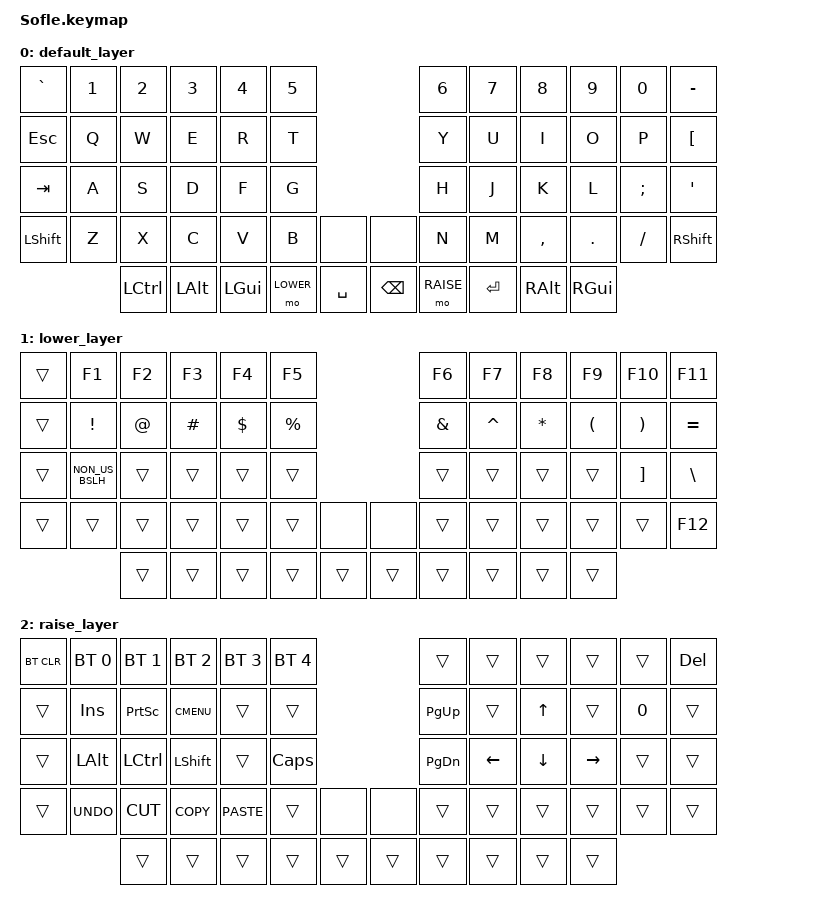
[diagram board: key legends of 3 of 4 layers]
/*
 * Copyright (c) 2020 The ZMK Contributors
 *
 * SPDX-License-Identifier: MIT
 */

#include <behaviors.dtsi>
#include <dt-bindings/zmk/keys.h>
#include <dt-bindings/zmk/bt.h>

#define BASE 0
#define LOWER 1
#define RAISE 2
#define ADJUST 3

/ {
    // Activate ADJUST layer by pressing raise and lower
    conditional_layers {
        compatible = "zmk,conditional-layers";
        adjust_layer {
            if-layers = <LOWER RAISE>;
            then-layer = <ADJUST>;
        };
    };

    keymap {
        compatible = "zmk,keymap";

        default_layer {
// ------------------------------------------------------------------------------------------------------------
// |  ½    |  1  |  2  |  3   |  4   |  5   |                   |  6   |  7    |  8    |  9   |   0   |   +   |
// |  ESC  |  Q  |  W  |  E   |  R   |  T   |                   |  Y   |  U    |  I    |  O   |   P   |   Å   |
// |  TAB  |  A  |  S  |  D   |  F   |  G   |                   |  H   |  J    |  K    |  L   |   Æ   |   Ø   |
// | SHIFT |  Z  |  X  |  C   |  V   |  B   | NONE |  | NONE |  N   |  M    |  ,    |  .   |   -   | SHIFT |
//               | CTL | ALT  | GUI  | LOWER| SPACE|  | BSPC | RAISE| ENTER | ALT   | GUI  |
          bindings = <
&kp GRAVE &kp N1 &kp N2   &kp N3   &kp N4    &kp N5                           &kp N6 &kp N7    &kp N8    &kp N9   &kp N0   &kp MINUS
&kp ESC   &kp Q  &kp W    &kp E    &kp R     &kp T                            &kp Y  &kp U     &kp I     &kp O    &kp P    &kp LBKT
&kp TAB   &kp A  &kp S    &kp D    &kp F     &kp G                            &kp H  &kp J     &kp K     &kp L    &kp SEMI &kp SQT
&kp LSHFT &kp Z  &kp X    &kp C    &kp V     &kp B      &none      &none      &kp N  &kp M     &kp COMMA &kp DOT  &kp FSLH &kp RSHFT
                 &kp LCTRL &kp LALT &kp LGUI &mo LOWER  &kp SPACE  &kp BSPC   &mo RAISE &kp RET &kp RALT  &kp RGUI
            >;
        };

        lower_layer {
// ------------------------------------------------------------------------------------------------------------
// |       |  F1 |  F2 |  F3  |  F4  |  F5  |                   |  F6  |  F7   |  F8   |  F9  |  F10  |  F11  |
// |       |  !  |  "  |  #   |  ¤   |  %   |                   |  &   |  /    |  (    |  )   |   =   |   ´   |
// |       |  <  |     |      |      |      |                   |      |       |       |      |   ¨   |   '   |
// |       |     |     |      |      |      |        |  |       |      |       |       |      |       |  F12  |
//               |     |      |      |      |        |  |       |      |       |       |      |
            bindings = <
&trans    &kp F1          &kp F2 &kp F3 &kp F4 &kp F5                           &kp F6   &kp F7    &kp F8    &kp F9   &kp F10  &kp F11
&trans    &kp EXCL        &kp AT &kp HASH &kp DLLR &kp PRCNT                    &kp AMPS &kp CARET &kp ASTRK &kp LPAR &kp RPAR &kp EQUAL
&trans    &kp NON_US_BSLH &trans &trans &trans &trans                           &trans   &trans    &trans    &trans   &kp RBKT &kp BSLH
&trans    &trans          &trans &trans &trans &trans    &none  &none           &trans   &trans    &trans    &trans   &trans   &kp F12
                          &trans &trans &trans &trans    &trans &trans          &trans   &trans    &trans    &trans
            >;
        };

        raise_layer {
// ------------------------------------------------------------------------------------------------------------
// | BTCLR | BT1  | BT2  |  BT3  |  BT4  |  BT5 |                |      |      |       |      |       |  DEL  |
// |       | INS  | PSCR | GUI   |       |      |                | PGUP |      |   ^   |      |       |       |
// |       | ALT  | CTRL | SHIFT |       | CAPS |                | PGDN |   <- |   v   |  ->  |       |       |
// |       | UNDO | CUT  | COPY  | PASTE |      |      |  |      |      |      |       |      |       |       |
//                |      |       |       |      |      |  |      |      |      |       |      |
            bindings = <
&bt BT_CLR &bt BT_SEL 0 &bt BT_SEL 1 &bt BT_SEL 2 &bt BT_SEL 3 &bt BT_SEL 4                    &trans    &trans    &trans   &trans    &trans  &kp DEL
&trans     &kp INS      &kp PSCRN    &kp K_CMENU  &trans       &trans                          &kp PG_UP &trans    &kp UP   &trans    &kp N0  &trans
&trans     &kp LALT     &kp LCTRL    &kp LSHFT    &trans       &kp CLCK                        &kp PG_DN &kp LEFT  &kp DOWN &kp RIGHT &trans  &trans
&trans     &kp K_UNDO   &kp K_CUT    &kp K_COPY   &kp K_PASTE  &trans       &none    &none     &trans    &trans    &trans   &trans    &trans  &trans
                        &trans       &trans       &trans       &trans       &trans   &trans    &trans    &trans    &trans   &trans
            >;
        };

        adjust_layer {
// ----------------------------------------------------------------------------------------------------------------------------
// | BTCLR  |  BT1    |  BT2    |   BT3   |   BT4   |   BT5   |                  |      |      |       |      |       |       |
// |        |         |         |         |         |         |                  |      |      |       |      |       |       |
// |        |         |         |         |         |         |                  |      |      |       |      |       |       |
// |        |         |         |         |         |         |         | |      |      |      |       |      |       |       |
//                    |         |         |         |         |         | |      |      |      |       |      |
            display-name = "adjust";
            bindings = <
&bt BT_CLR &bt BT_SEL 0 &bt BT_SEL 1 &bt BT_SEL 2 &bt BT_SEL 3 &bt BT_SEL 4                                    &none &none &none &none &none &none
&none      &none        &none        &none        &none        &none                                           &none &none &none &none &none &none
&none      &none        &none        &none        &none        &none                                           &none &none &none &none &none &none
&none      &none        &none        &none        &none        &none            &none &none                    &none &none &none &none &none &none
                                &none             &none        &none            &none &none                    &none &none &none &none
            >;
        };
    };
};
